# ZB204 register map
Vendor: GS; File version: 1.2
CPU: CM3 r2p0, little endian, MPU, no FPU, VTOR, 3 interrupt priority bits
Registers are 32-bit, read-write, reset 0x0 unless marked. A register's access mark holds for its fields unless they carry their own. Offsets are from the block's base; [hi:lo] are bit positions; {n}, {i} and the like mark numbered series.

## QSPI — QuadSPI
Base 0x40090000
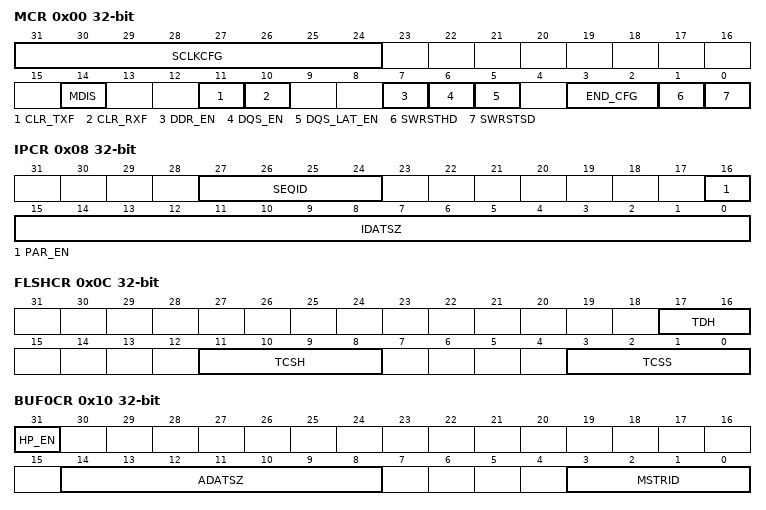
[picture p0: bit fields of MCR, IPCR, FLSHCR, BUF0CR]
0x00 MCR — Module_Configuration_Register
  [31:24] SCLKCFG — Serial Clock Configuration
  [14] MDIS — Module Disable
  [11] CLR_TXF — Clear TX FIFO/Buffer
  [10] CLR_RXF — Clear RX FIFO
  [7] DDR_EN — DDR mode enable
  [6] DQS_EN — DQS enable
  [5] DQS_LAT_EN — DQS Latency Enable
  [3:2] END_CFG — Defines the endianness of the QuadSPI module
  [1] SWRSTHD — Software reset for AHB domain
  [0] SWRSTSD — Software reset for serial flash domain
0x08 IPCR — IP_Configuration_Register
  [27:24] SEQID — Points to a sequence in the Look-up table
  [16] PAR_EN — When set, a transaction to two serial flash devices is triggered in parallel mode
  [15:0] IDATSZ — IP data transfer size
0x0C FLSHCR — Flash Configuration Register
  [17:16] TDH — Serial flash data in hold time
  [11:8] TCSH — Serial flash CS hold time in terms of serial flash clock cycles
  [3:0] TCSS — Serial flash CS setup time in terms of serial flash clock cycles
0x10 BUF0CR — Buffer0 Configuration Register
  [31] HP_EN — High Priority Enable
  [14:8] ADATSZ — AHB data transfer size
  [3:0] MSTRID — Master ID
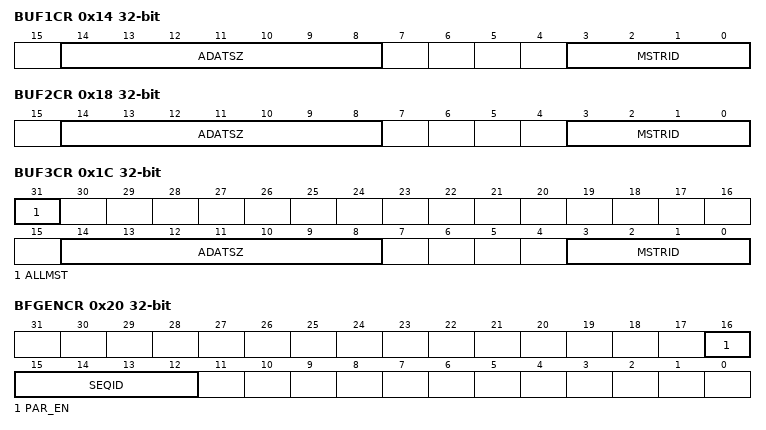
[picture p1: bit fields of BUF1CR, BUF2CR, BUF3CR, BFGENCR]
0x14 BUF1CR — Buffer1 Configuration Register
  [14:8] ADATSZ — AHB data transfer size
  [3:0] MSTRID — Master ID
0x18 BUF2CR — Buffer2 Configuration Register
  [14:8] ADATSZ — AHB data transfer size
  [3:0] MSTRID — Master ID
0x1C BUF3CR — Buffer3 Configuration Register
  [31] ALLMST — All master enable
  [14:8] ADATSZ — AHB data transfer size
  [3:0] MSTRID — Master ID
0x20 BFGENCR — Buffer Generic Configuration Register
  [16] PAR_EN — When set, a transaction to two serial flash devices is triggered in parallel mode
  [15:12] SEQID — Points to a sequence in the Look-up-table
0x24 SOCCR — SOC Configuration Register
  [31:0] SOCCFG — SOC Configuration
0x30 BUF0IND — Buffer0 Top Index Register
0x34 BUF1IND — Buffer1 Top Index Register
  [31:3] TPINDX1 — Top index of buffer 1
0x38 BUF2IND — Buffer2 Top Index Register
  [31:3] TPINDX2 — Top index of buffer 2
0x100 SFAR — Serial Flash Address Register
  [31:0] SFADR — Serial Flash Address
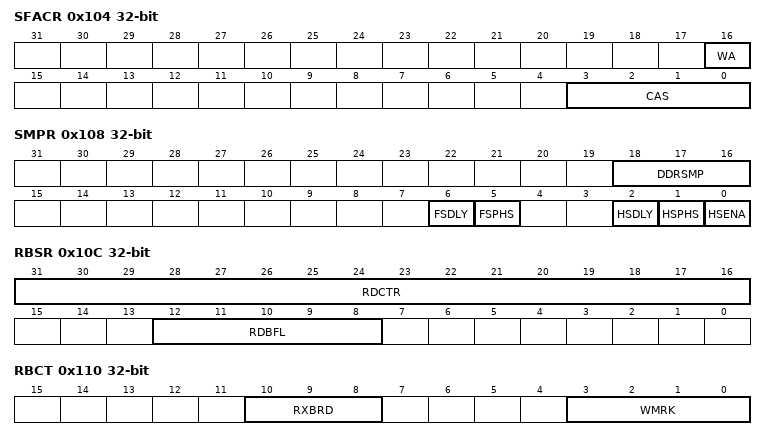
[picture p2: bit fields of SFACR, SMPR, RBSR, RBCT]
0x104 SFACR — Serial Flash Address Configuration Register
  [16] WA — Word Addressable
  [3:0] CAS — Column Address Space
0x108 SMPR — Sampling Register
  [18:16] DDRSMP — DDR Sampling point
  [6] FSDLY — Full Speed Delay selection for SDR instructions
  [5] FSPHS — Full Speed Phase selection for SDR instructions
  [2] HSDLY — Half Speed Delay selection for SDR instructions
  [1] HSPHS — Half Speed Phase selection for SDR instructions
  [0] HSENA — Half Speed serial flash clock Enable
0x10C RBSR — RX Buffer Status Register
  [31:16] RDCTR — Read Counter
  [12:8] RDBFL — RX Buffer Fill Level
0x110 RBCT — RX Buffer Control Register
  [10:8] RXBRD — RX Buffer Readout
  [3:0] WMRK — RX Buffer Watermark
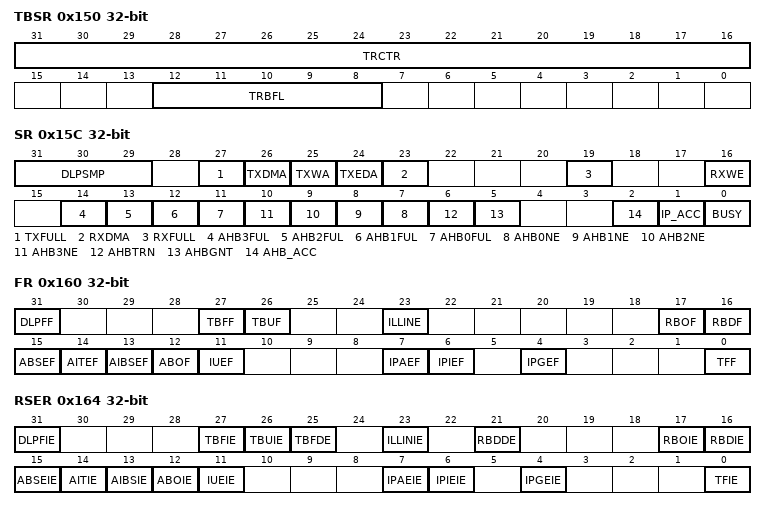
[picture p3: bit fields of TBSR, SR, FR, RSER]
0x150 TBSR — TX Buffer Status Register
  [31:16] TRCTR — Transmit Counter
  [12:8] TRBFL — TX Buffer Fill Level
0x154 TBDR — TX Buffer Data Register
  [31:0] TXDATA
0x158 TBCT — Tx Buffer Control Register
  [3:0] WMRK — Determines the watermark for the TX Buffer
0x15C SR — Status Register
  [31:29] DLPSMP — Data learning pattern sampling point
  [27] TXFULL — TX Buffer Full
  [26] TXDMA
  [25] TXWA — TX Buffer watermark Available
  [24] TXEDA — Tx Buffer Enough Data Available
  [23] RXDMA — RX Buffer DMA
  [19] RXFULL — RX Buffer Full
  [16] RXWE — RX Buffer Watermark Exceeded
  [14] AHB3FUL — AHB 3 Buffer Ful
  [13] AHB2FUL — AHB 2 Buffer Ful
  [12] AHB1FUL — AHB 1 Buffer Full
  [11] AHB0FUL — AHB 0 Buffer Full
  [n+7] AHB{n}NE (n=0..3) — AHB {n} Buffer Not Empty
  [6] AHBTRN — AHB Access Transaction pending
  [5] AHBGNT — AHB Command priority Granted
  [2] AHB_ACC — AHB Access
  [1] IP_ACC — IP Access
  [0] BUSY — Module Busy
0x160 FR — Flag Register
  [31] DLPFF — Data Learning Pattern Failure Flag
  [27] TBFF — TX Buffer Fill Flag
  [26] TBUF — TX Buffer Underrun Flag
  [23] ILLINE — Illegal Instruction Error Flag
  [17] RBOF — RX Buffer Overflow Flag
  [16] RBDF — RX Buffer Drain Flag
  [15] ABSEF — AHB Sequence Error Flag
  [14] AITEF — AHB Illegal transaction error flag
  [13] AIBSEF — AHB Illegal Burst Size Error Flag
  [12] ABOF — AHB Buffer Overflow Flag
  [11] IUEF — IP Command Usage Error Flag
  [7] IPAEF — IP Command Trigger during AHB Access Error Flag
  [6] IPIEF — IP Command Trigger could not be executed Error Flag
  [4] IPGEF — IP Command Trigger during AHB Grant Error Flag
  [0] TFF — IP Command Transaction Finished Flag
0x164 RSER — Interrupt and DMA Request Select and Enable Register
  [31] DLPFIE — Data Learning Pattern Failure Interrupt enable
  [27] TBFIE — TX Buffer Fill Interrupt Enable
  [26] TBUIE — TX Buffer Underrun Interrupt Enable
  [25] TBFDE — TX Buffer Fill DMA Enable
  [23] ILLINIE — Illegal Instruction Error Interrupt Enable
  [21] RBDDE — RX Buffer Drain DMA Enable
  [17] RBOIE — RX Buffer Overflow Interrupt Enable
  [16] RBDIE — RX Buffer Drain Interrupt Enable
  [15] ABSEIE — AHB Sequence Error Interrupt Enable
  [14] AITIE — AHB Illegal transaction interrupt enable
  [13] AIBSIE — AHB Illegal Burst Size Interrupt Enable
  [12] ABOIE — AHB Buffer Overflow Interrupt Enable
  [11] IUEIE — IP Command Usage Error Interrupt Enable
  [7] IPAEIE — IP Command Trigger during AHB Access Error Interrupt Enable
  [6] IPIEIE — IP Command Trigger during IP Access Error Interrupt Enable
  [4] IPGEIE — IP Command Trigger during AHB Grant Error Interrupt Enable
  [0] TFIE — Transaction Finished Interrupt Enable
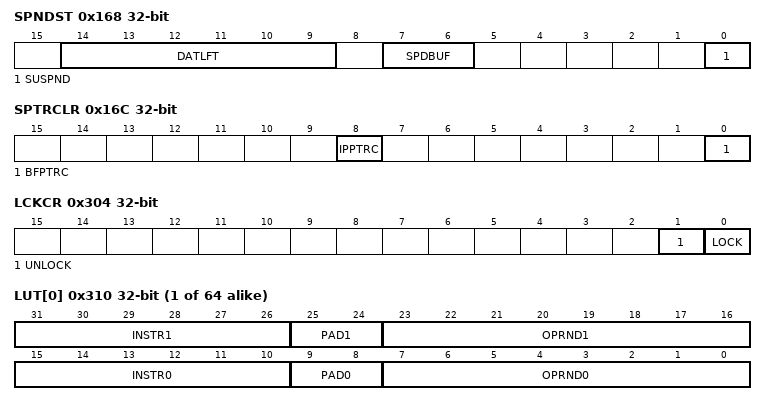
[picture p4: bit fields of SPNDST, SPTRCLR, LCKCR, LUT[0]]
0x168 SPNDST — Sequence Suspend Status Register
  [14:9] DATLFT — Data left
  [7:6] SPDBUF — Suspended Buffer
  [0] SUSPND — When set, it signifies that a sequence is in suspended state
0x16C SPTRCLR — Sequence Pointer Clear Register
  [8] IPPTRC — IP Pointer Clear
  [0] BFPTRC — Buffer Pointer Clear
0x180 SFA1AD — Serial Flash A1 Top Address
  [31:10] TPADA1 — Top address for Serial Flash A1
0x184 SFA2AD — Serial Flash A2 Top Address
  [31:10] TPADA2 — Top address for Serial Flash A2
0x188 SFB1AD — Serial Flash B1Top Address
  [31:10] TPADB1 — Top address for Serial Flash B1
0x18C SFB2AD — Serial Flash B2Top Address
  [31:10] TPADB2 — Top address for Serial Flash B2
0x190 DLPR — Data Learn Pattern Register
  [31:0] DLPV — Data Learning Pattern Value
{0x200+4i} RBDR[{i}] (i=0..15) — RX Buffer Data Register
  [31:0] RXDATA
0x300 LUTKEY
  [31:0] KEY — The key to lock or unlock the LUT
0x304 LCKCR — LUT Lock Configuration Register
  [1] UNLOCK — Unlocks the LUT when the following two conditions are met
  [0] LOCK — Locks the LUT when the following condition is met
{0x310+4i} LUT[{i}] (i=0..63) — look-up-table for sequences of instructions
  [31:26] INSTR1 — Instruction 1
  [25:24] PAD1 — Pad information for INSTR1
  [23:16] OPRND1 — Operand for INSTR1
  [15:10] INSTR0 — Instruction 0
  [9:8] PAD0 — Pad information for INSTR0
  [7:0] OPRND0 — Operand for INSTR0
